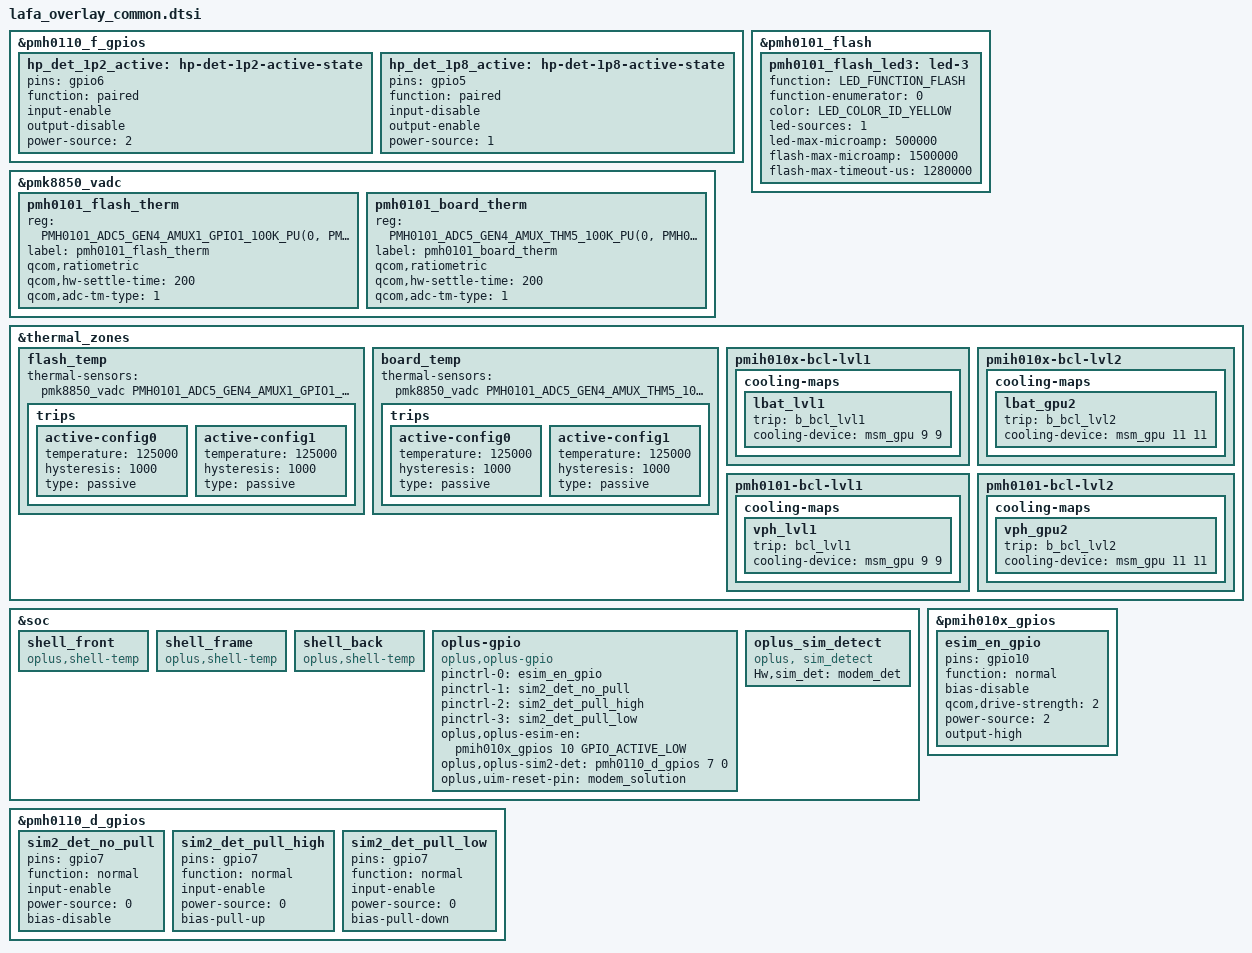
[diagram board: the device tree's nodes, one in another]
/*
 * Display, audio, BT, WLAN and eSE overlays are folded into the project dtbo
 * here.
 *
 * The OPPO BSP keeps the display and audio overlays as separate standalone
 * images built by their own module Makefiles
 * (vendor/qcom/opensource/{display,audio}-devicetree), so the BSP copy of this
 * file had no includes at all. Each of those trees is split in two, and it is
 * the .dts wrapper one directory over that pulls in the shared half:
 *
 *   qcom/display/oplus/lafa-24624-display-canoe-overlay.dts
 *       ../display/canoe-sde-display-mtp.dtsi     sde_dsi, sde_te_*, panels
 *       canoe-display-overlay-common.dtsi         oplus_sde_dsi_*
 *       lafa-24624-display-canoe-overlay.dtsi     lafa panels + pinctrl
 *       pxlw-lafa/pxlw-iris7p.dtsi                Pixelworks Iris7p
 *
 *   qcom/audio/oplus/lafa-24624-audio-canoe-overlay.dts
 *       ../canoe-audio-mtp.dtsi                   wsa/swr/wcd/va macros
 *       canoe-audio-overlay-common.dtsi
 *       lafa-24624-audio-canoe-overlay.dtsi       consumes hp_det_*
 *
 * In the LineageOS kernel tree the only dtbo that reaches the device is the one
 * listed in oplus/platform_map.bzl, so all of it has to be #included - same
 * pattern as fairlady-canoe-common.dtsi and infiniti-canoe-common.dtsi.
 *
 * Leaving them out is not a partial loss. lafa-24624-display-canoe-overlay.dtsi
 * references sde_dsi, sde_te_active, oplus_sde_dsi_active and
 * dsi_vtdr6130_amoled_video as phandles, and the audio dtsi references
 * wcd939x_codec, cdc_pri_mi2s_gpios, swr_haptics, wsa2_swr_gpios, clock_audio_*
 * and friends. Without their definitions those stay unresolved fixups in the
 * compiled .dtbo, so fdtoverlay (and therefore ABL) fails the whole overlay with
 * FDT_ERR_NOTFOUND and the device gets no device tree at all - it never boots,
 * it just falls back to fastboot.
 *
 * The camera overlay is included from lafa-24624-canoe-overlay.dtso instead,
 * because it exists in two hardware-stage variants.
 *
 * hp_det_1p2_active/hp_det_1p8_active are not defined in any shared file: the
 * audio wrapper .dts declares them, and the T0 wrapper declares the same labels
 * with gpio5/gpio6 swapped. This overlay covers the whole oplus,hw-id range, so
 * the values below are the production ones - the group the shipping dtbo
 * selects for retail units (see oplus/Makefile).
 */
#include "../qcom/bt/canoe-wcn786x-bt.dtsi"
#include "../qcom/eSE/canoe-ese-common.dtsi"
#include "../qcom/display/display/canoe-sde-display-mtp.dtsi"
#include "../qcom/display/oplus/canoe-display-overlay-common.dtsi"
#include "../qcom/display/oplus/lafa-24624-display-canoe-overlay.dtsi"
#include "../qcom/display/oplus/pxlw-lafa/pxlw-iris7p.dtsi"
#include "../qcom/wlan/oplus/canoe-peach-cnss-overlay.dtsi"
#include "../qcom/audio/canoe-audio-mtp.dtsi"
#include "../qcom/audio/oplus/canoe-audio-overlay-common.dtsi"
#include "../qcom/audio/oplus/lafa-24624-audio-canoe-overlay.dtsi"

&pmh0110_f_gpios {
	hp_det_1p2_active: hp-det-1p2-active-state {
		pins = "gpio6";
		function = "paired";
		input-enable;
		output-disable;
		power-source = <2>; /* 1.2v */
	};

	hp_det_1p8_active: hp-det-1p8-active-state {
		pins = "gpio5";
		function = "paired";
		input-disable;
		output-enable;
		power-source = <1>; /* 1.8v */
	};
};

&pmh0101_flash {
       pmh0101_flash_led3: led-3 {
		function = LED_FUNCTION_FLASH;
		function-enumerator = <0>;
		color = <LED_COLOR_ID_YELLOW>;
		led-sources = <1>;
		led-max-microamp = <500000>;
		flash-max-microamp = <1500000>;
		flash-max-timeout-us = <1280000>;
	};
};

&pmk8850_vadc {
        pmh0101_flash_therm {
                reg = <PMH0101_ADC5_GEN4_AMUX1_GPIO1_100K_PU(0, PMH0101_SID)>;
                label = "pmh0101_flash_therm";
                qcom,ratiometric;
                qcom,hw-settle-time = <200>;
                qcom,adc-tm-type = <1>;
        };
        pmh0101_board_therm {
                reg = <PMH0101_ADC5_GEN4_AMUX_THM5_100K_PU(0, PMH0101_SID)>;
                label = "pmh0101_board_therm";
                qcom,ratiometric;
                qcom,hw-settle-time = <200>;
                qcom,adc-tm-type = <1>;
        };
};

&thermal_zones {
        flash_temp {
                thermal-sensors = <&pmk8850_vadc
                                   PMH0101_ADC5_GEN4_AMUX1_GPIO1_100K_PU(0, PMH0101_SID)>;

                trips {
                        active-config0 {
                                temperature = <125000>;
                                hysteresis = <1000>;
                                type = "passive";
                        };

                        active-config1 {
                                temperature = <125000>;
                                hysteresis = <1000>;
                                type = "passive";
                        };
                };
        };
        board_temp {
                thermal-sensors = <&pmk8850_vadc
                                   PMH0101_ADC5_GEN4_AMUX_THM5_100K_PU(0, PMH0101_SID)>;

                trips {
                        active-config0 {
                                temperature = <125000>;
                                hysteresis = <1000>;
                                type = "passive";
                        };

                        active-config1 {
                                temperature = <125000>;
                                hysteresis = <1000>;
                                type = "passive";
                        };
                };
        };

        pmih010x-bcl-lvl1 {
            cooling-maps {
                lbat_lvl1 {
                    trip = <&b_bcl_lvl1>;
                    cooling-device = <&msm_gpu 9 9>;
                };
            };
        };

        pmih010x-bcl-lvl2 {
            cooling-maps {
                lbat_gpu2 {
                    trip = <&b_bcl_lvl2>;
                    cooling-device = <&msm_gpu 11 11>;
                };
            };
        };

        pmh0101-bcl-lvl1 {
            cooling-maps {
                vph_lvl1 {
                    trip = <&bcl_lvl1>;
                    cooling-device = <&msm_gpu 9 9>;
                };
            };
        };

        pmh0101-bcl-lvl2 {
            cooling-maps {
                vph_gpu2 {
                    trip = <&b_bcl_lvl2>;
                    cooling-device = <&msm_gpu 11 11>;
                };
            };
        };
};

&soc {
        //#ifdef OPLUS_FEATURE_THERMAL_HORAE
        shell_front {
                compatible = "oplus,shell-temp";
        };

        shell_frame {
                compatible = "oplus,shell-temp";
        };

        shell_back {
                compatible = "oplus,shell-temp";
        };
        //#endif /* OPLUS_FEATURE_THERMAL_HORAE */

        //#ifdef OPLUS_FEATURE_ESIM
        oplus-gpio {
           compatible = "oplus,oplus-gpio";
           pinctrl-names = "oplus_esim", "sim2_det_no_pull", "sim2_det_pull_high", "sim2_det_pull_low";
           pinctrl-0 = <&esim_en_gpio>;
           pinctrl-1 = <&sim2_det_no_pull>;
           pinctrl-2 = <&sim2_det_pull_high>;
           pinctrl-3 = <&sim2_det_pull_low>;
           oplus,oplus-esim-en = <&pmih010x_gpios 10 GPIO_ACTIVE_LOW>;
           oplus,oplus-sim2-det = <&pmh0110_d_gpios 7 0>;
           oplus,uim-reset-pin = "modem_solution";
        };
        oplus_sim_detect {
           compatible = "oplus, sim_detect";
           Hw,sim_det = "modem_det";
        };
        //#endif /*OPLUS_FEATURE_ESIM*/
};

&pmih010x_gpios {
  esim_en_gpio: esim_en_gpio {
      pins = "gpio10";
      function = "normal";
      bias-disable; /* NO pull */
      qcom,drive-strength = <2>; /* 2 MA */
      power-source = <2>; /* 1.2V */
      output-high;
  };
};

&pmh0110_d_gpios {
    sim2_det_no_pull: sim2_det_no_pull {
        pins = "gpio7";
        function = "normal";
        input-enable;
        power-source = <0>;
        bias-disable;
    };

    sim2_det_pull_high: sim2_det_pull_high {
        pins = "gpio7";
        function = "normal";
        input-enable;
        power-source = <0>;
        bias-pull-up;
    };

    sim2_det_pull_low: sim2_det_pull_low {
        pins = "gpio7";
        function = "normal";
        input-enable;
        power-source = <0>;
        bias-pull-down;
    };
};
